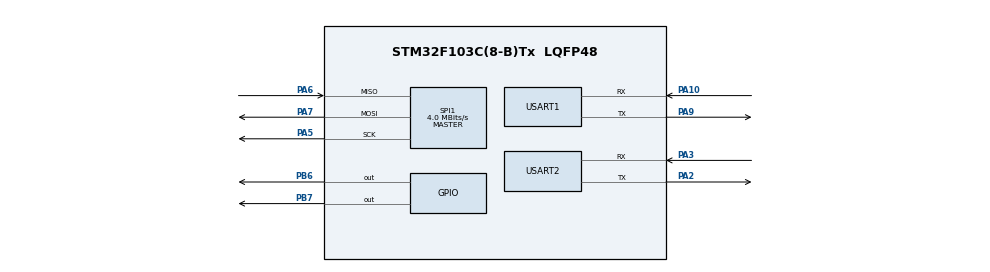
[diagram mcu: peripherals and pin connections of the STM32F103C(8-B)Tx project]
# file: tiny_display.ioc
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Dma.Request0=USART1_RX
Dma.Request1=USART1_TX
Dma.USART1_RX.0.Direction=DMA_PERIPH_TO_MEMORY
Dma.USART1_RX.0.Instance=DMA1_Channel5
Dma.USART1_RX.0.MemDataAlignment=DMA_MDATAALIGN_BYTE
Dma.USART1_RX.0.MemInc=DMA_MINC_ENABLE
Dma.USART1_RX.0.Mode=DMA_CIRCULAR
Dma.USART1_RX.0.PeriphDataAlignment=DMA_PDATAALIGN_BYTE
Dma.USART1_RX.0.PeriphInc=DMA_PINC_DISABLE
Dma.USART1_RX.0.Priority=DMA_PRIORITY_LOW
Dma.USART1_TX.1.Direction=DMA_MEMORY_TO_PERIPH
Dma.USART1_TX.1.Instance=DMA1_Channel4
Dma.USART1_TX.1.MemDataAlignment=DMA_MDATAALIGN_BYTE
Dma.USART1_TX.1.MemInc=DMA_MINC_ENABLE
Dma.USART1_TX.1.Mode=DMA_NORMAL
Dma.USART1_TX.1.PeriphDataAlignment=DMA_PDATAALIGN_BYTE
Dma.USART1_TX.1.PeriphInc=DMA_PINC_DISABLE
Dma.USART1_TX.1.Priority=DMA_PRIORITY_LOW
FREERTOS.Tasks01=defaultTask,24,128,StartDefaultTask,Default,NULL,Dynamic,NULL,NULL
Mcu.Family=STM32F1
Mcu.Name=STM32F103C(8-B)Tx
Mcu.Package=LQFP48
NVIC.DMA1_Channel4_IRQn=true\:6\:0\:true\:false\:true\:true\:false\:true\:true
NVIC.DMA1_Channel5_IRQn=true\:6\:0\:true\:false\:true\:true\:false\:true\:true
NVIC.PriorityGroup=NVIC_PRIORITYGROUP_4
NVIC.TIM3_IRQn=true\:15\:0\:false\:false\:true\:false\:false\:true\:true
NVIC.TimeBase=TIM3_IRQn
NVIC.TimeBaseIP=TIM3
PA10.Mode=Asynchronous
PA10.Signal=USART1_RX
PA13.Mode=Serial_Wire
PA13.Signal=SYS_JTMS-SWDIO
PA14.Mode=Serial_Wire
PA14.Signal=SYS_JTCK-SWCLK
PA2.Mode=Asynchronous
PA2.Signal=USART2_TX
PA3.Mode=Asynchronous
PA3.Signal=USART2_RX
PA5.Mode=Full_Duplex_Master
PA5.Signal=SPI1_SCK
PA6.Mode=Full_Duplex_Master
PA6.Signal=SPI1_MISO
PA7.Mode=Full_Duplex_Master
PA7.Signal=SPI1_MOSI
PA9.Mode=Asynchronous
PA9.Signal=USART1_TX
PB6.Signal=GPIO_Output
PB7.Signal=GPIO_Output
PC14-OSC32_IN.Mode=LSE-External-Oscillator
PC14-OSC32_IN.Signal=RCC_OSC32_IN
PC15-OSC32_OUT.Mode=LSE-External-Oscillator
PC15-OSC32_OUT.Signal=RCC_OSC32_OUT
PD0-OSC_IN.Mode=HSE-External-Oscillator
PD0-OSC_IN.Signal=RCC_OSC_IN
PD1-OSC_OUT.Mode=HSE-External-Oscillator
PD1-OSC_OUT.Signal=RCC_OSC_OUT
ProjectManager.HeapSize=0x200
ProjectManager.StackSize=0x400
ProjectManager.TargetToolchain=Makefile
RCC.APB1Freq_Value=8000000
RCC.APB2Freq_Value=8000000
SPI1.CalculateBaudRate=4.0 MBits/s
SPI1.Direction=SPI_DIRECTION_2LINES
SPI1.Mode=SPI_MODE_MASTER
SPI1.VirtualType=VM_MASTER
USART1.VirtualMode=VM_ASYNC
USART2.VirtualMode=VM_ASYNC
VP_FREERTOS_VS_CMSIS_V2.Mode=CMSIS_V2
VP_SYS_VS_tim3.Mode=TIM3
board=custom

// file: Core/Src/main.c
/* USER CODE BEGIN Header */
/**
 ******************************************************************************
 * @file           : main.c
 * @brief          : Main program body
 ******************************************************************************
 * @attention
 *
 * Copyright (c) 2022 STMicroelectronics.
 * All rights reserved.
 *
 * This software is licensed under terms that can be found in the LICENSE file
 * in the root directory of this software component.
 * If no LICENSE file comes with this software, it is provided AS-IS.
 *
 ******************************************************************************
 */
/* USER CODE END Header */
#include "main.h"
#include "cmsis_os.h"
#include "dma.h"
#include "gpio.h"
#include "spi.h"
#include "usart.h"

void SystemClock_Config(void);
void MX_FREERTOS_Init(void);

int main(void) {

  /* MCU Configuration--------------------------------------------------------*/

  /* Reset of all peripherals, Initializes the Flash interface and the Systick.
   */
  HAL_Init();

  /* Configure the system clock */
  SystemClock_Config();

  /* Initialize all configured peripherals */
  MX_GPIO_Init();
  MX_DMA_Init();
  MX_USART1_UART_Init();
  MX_USART2_UART_Init();
  MX_SPI1_Init();

  /* Init scheduler */
  osKernelInitialize(); /* Call init function for freertos objects (in
                           freertos.c) */
  MX_FREERTOS_Init();

  /* Start scheduler */
  osKernelStart();

  /* We should never get here as control is now taken by the scheduler */
  /* Infinite loop */
  while (1) {

  }
}

void SystemClock_Config(void) {
  RCC_OscInitTypeDef RCC_OscInitStruct = {0};
  RCC_ClkInitTypeDef RCC_ClkInitStruct = {0};

  /** Initializes the RCC Oscillators according to the specified parameters
   * in the RCC_OscInitTypeDef structure.
   */
  RCC_OscInitStruct.OscillatorType = RCC_OSCILLATORTYPE_HSI;
  RCC_OscInitStruct.HSIState = RCC_HSI_ON;
  RCC_OscInitStruct.HSICalibrationValue = RCC_HSICALIBRATION_DEFAULT;
  RCC_OscInitStruct.PLL.PLLState = RCC_PLL_NONE;
  if (HAL_RCC_OscConfig(&RCC_OscInitStruct) != HAL_OK) {
    Error_Handler();
  }

  /** Initializes the CPU, AHB and APB buses clocks
   */
  RCC_ClkInitStruct.ClockType = RCC_CLOCKTYPE_HCLK | RCC_CLOCKTYPE_SYSCLK |
                                RCC_CLOCKTYPE_PCLK1 | RCC_CLOCKTYPE_PCLK2;
  RCC_ClkInitStruct.SYSCLKSource = RCC_SYSCLKSOURCE_HSI;
  RCC_ClkInitStruct.AHBCLKDivider = RCC_SYSCLK_DIV1;
  RCC_ClkInitStruct.APB1CLKDivider = RCC_HCLK_DIV1;
  RCC_ClkInitStruct.APB2CLKDivider = RCC_HCLK_DIV1;

  if (HAL_RCC_ClockConfig(&RCC_ClkInitStruct, FLASH_LATENCY_0) != HAL_OK) {
    Error_Handler();
  }
}

void HAL_TIM_PeriodElapsedCallback(TIM_HandleTypeDef *htim) {
  if (htim->Instance == TIM3) {
    HAL_IncTick();
  }
}

void Error_Handler(void) {
  /* USER CODE BEGIN Error_Handler_Debug */
  /* User can add his own implementation to report the HAL error return state
   */
  __disable_irq();
  while (1) {
  }
  /* USER CODE END Error_Handler_Debug */
}

#ifdef USE_FULL_ASSERT
/**
 * @brief  Reports the name of the source file and the source line number
 *         where the assert_param error has occurred.
 * @param  file: pointer to the source file name
 * @param  line: assert_param error line source number
 * @retval None
 */
void assert_failed(uint8_t *file, uint32_t line) {
  /* USER CODE BEGIN 6 */
  /* User can add his own implementation to report the file name and line
     number, ex: printf("Wrong parameters value: file %s on line %d\r\n",
     file, line) */
  /* USER CODE END 6 */
}
#endif /* USE_FULL_ASSERT */

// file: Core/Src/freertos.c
/* USER CODE BEGIN Header */
// /**
//  ******************************************************************************
//  * File Name          : freertos.c
//  * Description        : Code for freertos applications
//  ******************************************************************************
//  * @attention
//  *
//  * Copyright (c) 2022 STMicroelectronics.
//  * All rights reserved.
//  *
//  * This software is licensed under terms that can be found in the LICENSE
//  file
//  * in the root directory of this software component.
//  * If no LICENSE file comes with this software, it is provided AS-IS.
//  *
//  ******************************************************************************
//  */
/* USER CODE END Header */

#include "FreeRTOS.h"
#include "cmsis_os.h"
#include "main.h"
#include "task.h"

/* USER CODE BEGIN Includes */
#include "app-framework.h"
/* USER CODE END Includes */

/* Definitions for defaultTask */
osThreadId_t defaultTaskHandle;
const osThreadAttr_t defaultTask_attributes = {
    .name = "defaultTask",
    .stack_size = 128 * 4,
    .priority = (osPriority_t)osPriorityNormal,
};

void StartDefaultTask(void *argument);

void MX_FREERTOS_Init(void); /* (MISRA C 2004 rule 8.1) */

void MX_FREERTOS_Init(void) {
  /* USER CODE BEGIN Init */
  AppOnBoot();
  AppOnSetup();
  /* USER CODE END Init */

  /* USER CODE BEGIN RTOS_MUTEX */
  //     /* add mutexes, ... */
  /* USER CODE END RTOS_MUTEX */

  /* USER CODE BEGIN RTOS_SEMAPHORES */
  //     /* add semaphores, ... */
  /* USER CODE END RTOS_SEMAPHORES */

  /* USER CODE BEGIN RTOS_TIMERS */
  //     /* start timers, add new ones, ... */
  /* USER CODE END RTOS_TIMERS */

  /* USER CODE BEGIN RTOS_QUEUES */
  //     /* add queues, ... */
  /* USER CODE END RTOS_QUEUES */

  /* Create the thread(s) */
  /* creation of defaultTask */
  defaultTaskHandle =
      osThreadNew(StartDefaultTask, NULL, &defaultTask_attributes);

  /* USER CODE BEGIN RTOS_THREADS */
  //     /* add threads, ... */
  /* USER CODE END RTOS_THREADS */

  /* USER CODE BEGIN RTOS_EVENTS */
  //     /* add events, ... */
  /* USER CODE END RTOS_EVENTS */
}

/* USER CODE BEGIN Header_StartDefaultTask */
// /**
//  * @brief  Function implementing the defaultTask thread.
//  * @param  argument: Not used
//  * @retval None
//  */
/* USER CODE END Header_StartDefaultTask */
void StartDefaultTask(void *argument) {
  /* USER CODE BEGIN StartDefaultTask */
  /* Infinite loop */
  AppOnRun();
  for (;;) {

    osDelay(1);
  }
  /* USER CODE END StartDefaultTask */
}
